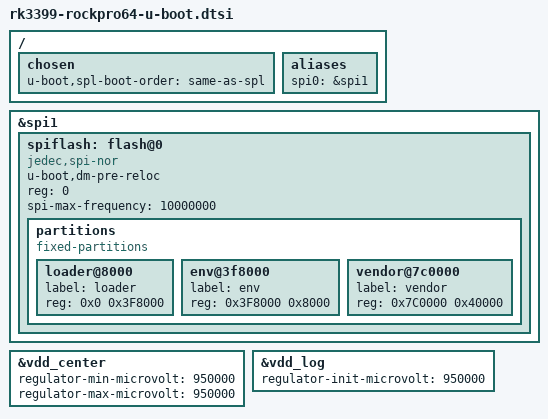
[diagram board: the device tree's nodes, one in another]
// SPDX-License-Identifier: GPL-2.0+
/*
 * Copyright (C) 2019 Jagan Teki <jagan@amarulasolutions.com>
 */

#include "rk3399-u-boot.dtsi"
#include "rk3399-sdram-lpddr4-100.dtsi"
/ {
	chosen {
		u-boot,spl-boot-order = "same-as-spl", &spiflash, &sdmmc, &sdhci;
	};

	aliases {
		spi0 = &spi1;
	};
};

&spi1 {
	status = "okay";

	spiflash: flash@0 {
		u-boot,dm-pre-reloc;
		compatible = "jedec,spi-nor";
		reg = <0>;
		spi-max-frequency = <10000000>;
		#address-cells = <1>;
		#size-cells = <1>;
		status = "okay";

		partitions {
			compatible = "fixed-partitions";
			#address-cells = <1>;
			#size-cells = <1>;

			loader@8000 {
				label = "loader";
				reg = <0x0 0x3F8000>;
			};

			env@3f8000 {
				label = "env";
				reg = <0x3F8000 0x8000>;
			};

			vendor@7c0000 {
				label = "vendor";
				reg = <0x7C0000 0x40000>;
			};
		};
	};
};

&vdd_center {
	regulator-min-microvolt = <950000>;
	regulator-max-microvolt = <950000>;
};

&vdd_log {
	regulator-init-microvolt = <950000>;
};
